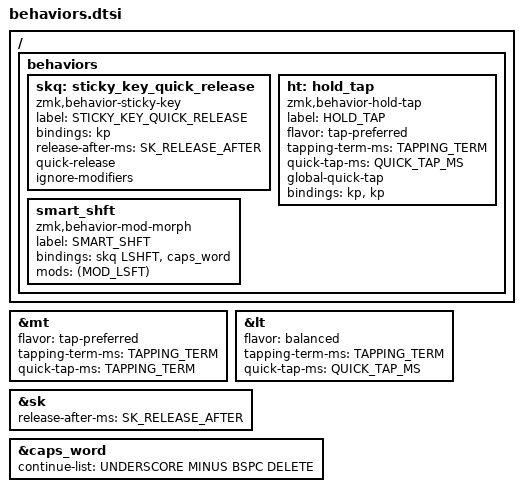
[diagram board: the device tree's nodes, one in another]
// Copyright 2023 saikocat (@saikocat)
// SPDX-License-Identifier: MIT

#include <behaviors.dtsi>

#include "behaviors.h"

&mt {
    flavor = "tap-preferred";
    tapping-term-ms = <TAPPING_TERM>;
    quick-tap-ms = <TAPPING_TERM>;          // disable TAPPING_FORCE_HOLD - allow holding down BSPC repeatedly
};

&lt {
    flavor = "balanced";
    tapping-term-ms = <TAPPING_TERM>;
    quick-tap-ms = <QUICK_TAP_MS>;
};

&sk {
    release-after-ms = <SK_RELEASE_AFTER>;
};

&caps_word {
    continue-list = <UNDERSCORE MINUS BSPC DELETE>;
};

/ {
    behaviors {
        skq: sticky_key_quick_release {
            label = "STICKY_KEY_QUICK_RELEASE";
            compatible = "zmk,behavior-sticky-key";
            #binding-cells = <1>;
            bindings = <&kp>;
            release-after-ms = <SK_RELEASE_AFTER>;
            quick-release;
            ignore-modifiers;
        };

        ht: hold_tap {
            label = "HOLD_TAP";
            compatible = "zmk,behavior-hold-tap";
            #binding-cells = <2>;
            flavor = "tap-preferred";
            tapping-term-ms = <TAPPING_TERM>;
            quick-tap-ms = <QUICK_TAP_MS>;
            global-quick-tap;
            bindings = <&kp>, <&kp>;
        };

        // tap: sticky-shift | shift + tap/ double-tap: caps-word | hold: shift
        smart_shft: smart_shft {
            label = "SMART_SHFT";
            compatible = "zmk,behavior-mod-morph";
            #binding-cells = <0>;
            bindings = <&skq LSHFT>, <&caps_word>;
            mods = <(MOD_LSFT)>;
        };
    };
};
